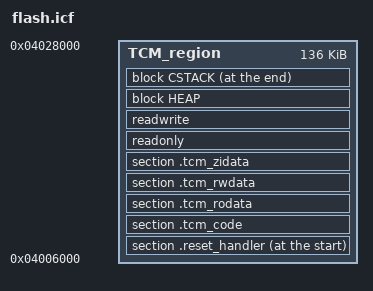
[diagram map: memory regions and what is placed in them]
/*###ICF### Section handled by ICF editor, don't touch! ****/
/*-Editor annotation file-*/
/* IcfEditorFile="$TOOLKIT_DIR$\config\ide\IcfEditor\cortex_v1_0.xml" */
/*-Specials-*/
define symbol __ICFEDIT_intvec_start__ = 0x00000000;
/*-Memory Regions-*/
define symbol __ICFEDIT_region_ROM_start__ = 0x08000000;
define symbol __ICFEDIT_region_ROM_end__   = 0x08010000;
define symbol __ICFEDIT_region_TCM_start__ = 0x04006000;
define symbol __ICFEDIT_region_TCM_end__   = 0x04028000;
/*-Sizes-*/
define symbol __ICFEDIT_size_cstack__ = 0x400;
define symbol __ICFEDIT_size_heap__   = 0x0;
/**** End of ICF editor section. ###ICF###*/

define memory mem with size = 4G;
define region TCM_region      = mem:[from __ICFEDIT_region_TCM_start__   to __ICFEDIT_region_TCM_end__];

define block CSTACK    with alignment = 8, size = __ICFEDIT_size_cstack__   { };
define block HEAP      with alignment = 8, size = __ICFEDIT_size_heap__     { };
/*
define block RAM_BLOCK with fixed order { section .ram_code,
                                          section .ram_rodata,
                                          readwrite
                                        };

define block TCM_BLOCK with fixed order { section .tcm_code,
                                          section .tcm_rodata,
                                          section .tcm_rwdata,
                                          section .tcm_zidata
                                        };
*/
/*
initialize by copy { section .intvec };
initialize by copy { section .ram_code };
initialize by copy { section .ram_rodata };
initialize by copy { readwrite };
initialize by copy { section .tcm_code };
initialize by copy { section .tcm_rodata };
initialize by copy { section .tcm_rwdata };

do not initialize  { section .noinit };
*/

place at start of TCM_region   { section .reset_handler  };
place in TCM_region            { section .tcm_code};
place in TCM_region            { section .tcm_rodata};
place in TCM_region            { section .tcm_rwdata};
place in TCM_region            { section .tcm_zidata};
place in TCM_region            { readonly};
place in TCM_region            { readwrite};
place in TCM_region            { block HEAP};

/*place in TCM_region            { readonly,block TCM_BLOCK,block RAM_BLOCK,block HEAP};*/
place at end of TCM_region     { block CSTACK };                        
